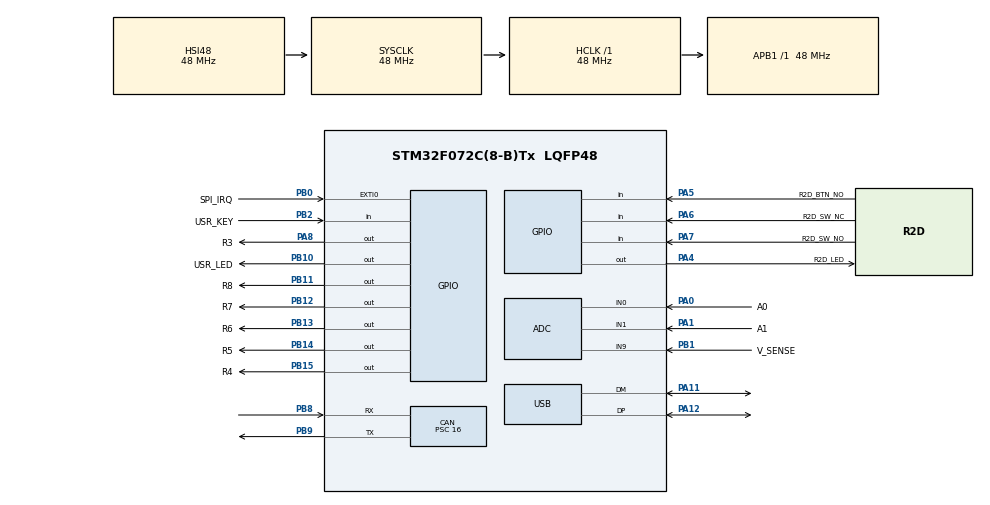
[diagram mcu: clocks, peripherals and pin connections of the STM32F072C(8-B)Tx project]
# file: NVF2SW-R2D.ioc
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ADC.ContinuousConvMode=DISABLE
CAN.BS1=CAN_BS1_3TQ
CAN.BS2=CAN_BS2_2TQ
CAN.CalculateBaudRate=500000
CAN.CalculateTimeBit=2000
CAN.CalculateTimeQuantum=333.3333333333333
CAN.Mode=CAN_MODE_NORMAL
CAN.Prescaler=16
CAN.TTCM=ENABLE
Mcu.Family=STM32F0
Mcu.Name=STM32F072C(8-B)Tx
Mcu.Package=LQFP48
NVIC.CEC_CAN_IRQn=true\:0\:0\:false\:false\:true\:true\:true\:true
NVIC.TIM16_IRQn=true\:0\:0\:false\:false\:true\:true\:true\:true
NVIC.USB_IRQn=true\:0\:0\:false\:false\:true\:false\:true\:true
PA0.GPIO_Label=A0
PA0.Mode=IN0
PA0.Signal=ADC_IN0
PA1.GPIO_Label=A1
PA1.Mode=IN1
PA1.Signal=ADC_IN1
PA11.Mode=Device
PA11.Signal=USB_DM
PA12.Mode=Device
PA12.Signal=USB_DP
PA13.Mode=Serial_Wire
PA13.Signal=SYS_SWDIO
PA14.Mode=Serial_Wire
PA14.Signal=SYS_SWCLK
PA4.GPIO_Label=R2D_LED
PA4.GPIO_ModeDefaultOutputPP=GPIO_MODE_OUTPUT_PP
PA4.GPIO_PuPd=GPIO_PULLUP
PA4.Signal=GPIO_Output
PA5.GPIO_Label=R2D_BTN_NO
PA5.GPIO_PuPd=GPIO_PULLDOWN
PA5.Signal=GPIO_Input
PA6.GPIO_Label=R2D_SW_NC
PA6.GPIO_PuPd=GPIO_PULLUP
PA6.Signal=GPIO_Input
PA7.GPIO_Label=R2D_SW_NO
PA7.GPIO_PuPd=GPIO_PULLDOWN
PA7.Signal=GPIO_Input
PA8.GPIO_Label=R3
PA8.Signal=GPIO_Output
PB0.GPIO_Label=SPI_IRQ
PB0.GPIO_ModeDefaultEXTI=GPIO_MODE_IT_RISING_FALLING
PB0.Signal=GPXTI0
PB1.GPIO_Label=V_SENSE
PB1.Mode=IN9
PB1.Signal=ADC_IN9
PB10.GPIO_Label=USR_LED
PB10.GPIO_ModeDefaultOutputPP=GPIO_MODE_OUTPUT_OD
PB10.GPIO_PuPd=GPIO_NOPULL
PB10.Signal=GPIO_Output
PB11.GPIO_Label=R8
PB11.Signal=GPIO_Output
PB12.GPIO_Label=R7
PB12.Signal=GPIO_Output
PB13.GPIO_Label=R6
PB13.Signal=GPIO_Output
PB14.GPIO_Label=R5
PB14.Signal=GPIO_Output
PB15.GPIO_Label=R4
PB15.Signal=GPIO_Output
PB2.GPIO_Label=USR_KEY
PB2.Signal=GPIO_Input
PB8.Mode=CAN_Activate
PB8.Signal=CAN_RX
PB9.Mode=CAN_Activate
PB9.Signal=CAN_TX
ProjectManager.HeapSize=0x200
ProjectManager.StackSize=0x400
ProjectManager.TargetToolchain=STM32CubeIDE
RCC.AHBFreq_Value=48000000
RCC.APB1Freq_Value=48000000
RCC.APB1TimFreq_Value=48000000
RCC.HCLKFreq_Value=48000000
RCC.SYSCLKFreq_VALUE=48000000
RCC.SYSCLKSource=RCC_SYSCLKSOURCE_HSI48
TIM16.AutoReloadPreload=TIM_AUTORELOAD_PRELOAD_ENABLE
TIM16.Period=10000-1
TIM16.Prescaler=480-1
USB_DEVICE.CLASS_NAME_FS=CDC
USB_DEVICE.MANUFACTURER_STRING=NVF2
USB_DEVICE.PRODUCT_STRING_CDC_FS=Small-General
USB_DEVICE.VirtualMode=Cdc
USB_DEVICE.VirtualModeFS=Cdc_FS
VP_ADC_TempSens_Input.Mode=IN-TempSens
VP_ADC_Vbat_Input.Mode=IN-Vbat
VP_ADC_Vref_Input.Mode=IN-Vrefint
VP_TIM15_VS_ClockSourceINT.Mode=Internal
VP_TIM16_VS_ClockSourceINT.Mode=Enable_Timer
VP_USB_DEVICE_VS_USB_DEVICE_CDC_FS.Mode=CDC_FS
board=custom

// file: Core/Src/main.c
/* USER CODE BEGIN Header */
/**
  ******************************************************************************
  * @file           : main.c
  * @brief          : Main program body
  ******************************************************************************
  * @attention
  *
  * Copyright (c) 2024 STMicroelectronics.
  * All rights reserved.
  *
  * This software is licensed under terms that can be found in the LICENSE file
  * in the root directory of this software component.
  * If no LICENSE file comes with this software, it is provided AS-IS.
  *
  ******************************************************************************
  */
/* USER CODE END Header */
#include "main.h"
#include "usb_device.h"

/* USER CODE BEGIN Includes */

#include "app.h"

/* USER CODE END Includes */

ADC_HandleTypeDef hadc;

CAN_HandleTypeDef hcan;

TIM_HandleTypeDef htim15;
TIM_HandleTypeDef htim16;

void SystemClock_Config(void);
static void MX_GPIO_Init(void);
static void MX_ADC_Init(void);
static void MX_CAN_Init(void);
static void MX_TIM16_Init(void);
static void MX_TIM15_Init(void);

/* USER CODE BEGIN 0 */
canbus_msg rxmsg;
void HAL_CAN_RxFifo0MsgPendingCallback(CAN_HandleTypeDef *hcan)
{
	static CAN_RxHeaderTypeDef rxHeader;
	cb_can_rx(hcan, &rxmsg, &rxHeader);
	cb_app(&rxmsg, &rxHeader);
}

void HAL_TIM_PeriodElapsedCallback(TIM_HandleTypeDef *htim)
{
  if (htim == &htim16)
  {
    task_app();
  }
}
/* USER CODE END 0 */

int main(void)
{

  /* MCU Configuration--------------------------------------------------------*/

  /* Reset of all peripherals, Initializes the Flash interface and the Systick. */
  HAL_Init();

  /* Configure the system clock */
  SystemClock_Config();

  /* Initialize all configured peripherals */
  MX_GPIO_Init();
  MX_ADC_Init();
  MX_CAN_Init();
  MX_USB_DEVICE_Init();
  MX_TIM16_Init();
  MX_TIM15_Init();
  /* USER CODE BEGIN 2 */
  HAL_TIM_Base_Start_IT(&htim16);

  init_app();
  /* USER CODE END 2 */

  /* Infinite loop */
  while (1)
  {

  }
}

void SystemClock_Config(void)
{
  RCC_OscInitTypeDef RCC_OscInitStruct = {0};
  RCC_ClkInitTypeDef RCC_ClkInitStruct = {0};
  RCC_PeriphCLKInitTypeDef PeriphClkInit = {0};

  /** Initializes the RCC Oscillators according to the specified parameters
  * in the RCC_OscInitTypeDef structure.
  */
  RCC_OscInitStruct.OscillatorType = RCC_OSCILLATORTYPE_HSI14|RCC_OSCILLATORTYPE_HSI48;
  RCC_OscInitStruct.HSI48State = RCC_HSI48_ON;
  RCC_OscInitStruct.HSI14State = RCC_HSI14_ON;
  RCC_OscInitStruct.HSI14CalibrationValue = 16;
  RCC_OscInitStruct.PLL.PLLState = RCC_PLL_NONE;
  if (HAL_RCC_OscConfig(&RCC_OscInitStruct) != HAL_OK)
  {
    Error_Handler();
  }

  /** Initializes the CPU, AHB and APB buses clocks
  */
  RCC_ClkInitStruct.ClockType = RCC_CLOCKTYPE_HCLK|RCC_CLOCKTYPE_SYSCLK
                              |RCC_CLOCKTYPE_PCLK1;
  RCC_ClkInitStruct.SYSCLKSource = RCC_SYSCLKSOURCE_HSI48;
  RCC_ClkInitStruct.AHBCLKDivider = RCC_SYSCLK_DIV1;
  RCC_ClkInitStruct.APB1CLKDivider = RCC_HCLK_DIV1;

  if (HAL_RCC_ClockConfig(&RCC_ClkInitStruct, FLASH_LATENCY_1) != HAL_OK)
  {
    Error_Handler();
  }
  PeriphClkInit.PeriphClockSelection = RCC_PERIPHCLK_USB;
  PeriphClkInit.UsbClockSelection = RCC_USBCLKSOURCE_HSI48;

  if (HAL_RCCEx_PeriphCLKConfig(&PeriphClkInit) != HAL_OK)
  {
    Error_Handler();
  }
}

static void MX_ADC_Init(void)
{

  ADC_ChannelConfTypeDef sConfig = {0};

  /** Configure the global features of the ADC (Clock, Resolution, Data Alignment and number of conversion)
  */
  hadc.Instance = ADC1;
  hadc.Init.ClockPrescaler = ADC_CLOCK_ASYNC_DIV1;
  hadc.Init.Resolution = ADC_RESOLUTION_12B;
  hadc.Init.DataAlign = ADC_DATAALIGN_RIGHT;
  hadc.Init.ScanConvMode = ADC_SCAN_DIRECTION_FORWARD;
  hadc.Init.EOCSelection = ADC_EOC_SINGLE_CONV;
  hadc.Init.LowPowerAutoWait = DISABLE;
  hadc.Init.LowPowerAutoPowerOff = DISABLE;
  hadc.Init.ContinuousConvMode = DISABLE;
  hadc.Init.DiscontinuousConvMode = DISABLE;
  hadc.Init.ExternalTrigConv = ADC_SOFTWARE_START;
  hadc.Init.ExternalTrigConvEdge = ADC_EXTERNALTRIGCONVEDGE_NONE;
  hadc.Init.DMAContinuousRequests = DISABLE;
  hadc.Init.Overrun = ADC_OVR_DATA_PRESERVED;
  if (HAL_ADC_Init(&hadc) != HAL_OK)
  {
    Error_Handler();
  }

  /** Configure for the selected ADC regular channel to be converted.
  */
  sConfig.Channel = ADC_CHANNEL_0;
  sConfig.Rank = ADC_RANK_CHANNEL_NUMBER;
  sConfig.SamplingTime = ADC_SAMPLETIME_1CYCLE_5;
  if (HAL_ADC_ConfigChannel(&hadc, &sConfig) != HAL_OK)
  {
    Error_Handler();
  }

  /** Configure for the selected ADC regular channel to be converted.
  */
  sConfig.Channel = ADC_CHANNEL_1;
  if (HAL_ADC_ConfigChannel(&hadc, &sConfig) != HAL_OK)
  {
    Error_Handler();
  }

  /** Configure for the selected ADC regular channel to be converted.
  */
  sConfig.Channel = ADC_CHANNEL_9;
  if (HAL_ADC_ConfigChannel(&hadc, &sConfig) != HAL_OK)
  {
    Error_Handler();
  }

  /** Configure for the selected ADC regular channel to be converted.
  */
  sConfig.Channel = ADC_CHANNEL_TEMPSENSOR;
  if (HAL_ADC_ConfigChannel(&hadc, &sConfig) != HAL_OK)
  {
    Error_Handler();
  }

  /** Configure for the selected ADC regular channel to be converted.
  */
  sConfig.Channel = ADC_CHANNEL_VREFINT;
  if (HAL_ADC_ConfigChannel(&hadc, &sConfig) != HAL_OK)
  {
    Error_Handler();
  }

  /** Configure for the selected ADC regular channel to be converted.
  */
  sConfig.Channel = ADC_CHANNEL_VBAT;
  if (HAL_ADC_ConfigChannel(&hadc, &sConfig) != HAL_OK)
  {
    Error_Handler();
  }

}

static void MX_CAN_Init(void)
{

  hcan.Instance = CAN;
  hcan.Init.Prescaler = 16;
  hcan.Init.Mode = CAN_MODE_NORMAL;
  hcan.Init.SyncJumpWidth = CAN_SJW_1TQ;
  hcan.Init.TimeSeg1 = CAN_BS1_3TQ;
  hcan.Init.TimeSeg2 = CAN_BS2_2TQ;
  hcan.Init.TimeTriggeredMode = ENABLE;
  hcan.Init.AutoBusOff = DISABLE;
  hcan.Init.AutoWakeUp = DISABLE;
  hcan.Init.AutoRetransmission = DISABLE;
  hcan.Init.ReceiveFifoLocked = DISABLE;
  hcan.Init.TransmitFifoPriority = DISABLE;
  if (HAL_CAN_Init(&hcan) != HAL_OK)
  {
    Error_Handler();
  }

}

static void MX_TIM15_Init(void)
{

  TIM_ClockConfigTypeDef sClockSourceConfig = {0};
  TIM_MasterConfigTypeDef sMasterConfig = {0};

  htim15.Instance = TIM15;
  htim15.Init.Prescaler = 0;
  htim15.Init.CounterMode = TIM_COUNTERMODE_UP;
  htim15.Init.Period = 65535;
  htim15.Init.ClockDivision = TIM_CLOCKDIVISION_DIV1;
  htim15.Init.RepetitionCounter = 0;
  htim15.Init.AutoReloadPreload = TIM_AUTORELOAD_PRELOAD_DISABLE;
  if (HAL_TIM_Base_Init(&htim15) != HAL_OK)
  {
    Error_Handler();
  }
  sClockSourceConfig.ClockSource = TIM_CLOCKSOURCE_INTERNAL;
  if (HAL_TIM_ConfigClockSource(&htim15, &sClockSourceConfig) != HAL_OK)
  {
    Error_Handler();
  }
  sMasterConfig.MasterOutputTrigger = TIM_TRGO_RESET;
  sMasterConfig.MasterSlaveMode = TIM_MASTERSLAVEMODE_DISABLE;
  if (HAL_TIMEx_MasterConfigSynchronization(&htim15, &sMasterConfig) != HAL_OK)
  {
    Error_Handler();
  }

}

static void MX_TIM16_Init(void)
{

  htim16.Instance = TIM16;
  htim16.Init.Prescaler = 480-1;
  htim16.Init.CounterMode = TIM_COUNTERMODE_UP;
  htim16.Init.Period = 10000-1;
  htim16.Init.ClockDivision = TIM_CLOCKDIVISION_DIV1;
  htim16.Init.RepetitionCounter = 0;
  htim16.Init.AutoReloadPreload = TIM_AUTORELOAD_PRELOAD_ENABLE;
  if (HAL_TIM_Base_Init(&htim16) != HAL_OK)
  {
    Error_Handler();
  }

}

static void MX_GPIO_Init(void)
{
  GPIO_InitTypeDef GPIO_InitStruct = {0};

  /* GPIO Ports Clock Enable */
  __HAL_RCC_GPIOC_CLK_ENABLE();
  __HAL_RCC_GPIOF_CLK_ENABLE();
  __HAL_RCC_GPIOA_CLK_ENABLE();
  __HAL_RCC_GPIOB_CLK_ENABLE();

  /*Configure GPIO pin Output Level */
  HAL_GPIO_WritePin(GPIOA, R2D_LED_Pin|R3_Pin, GPIO_PIN_RESET);

  /*Configure GPIO pin Output Level */
  HAL_GPIO_WritePin(GPIOB, USR_LED_Pin|R8_Pin|R7_Pin|R6_Pin
                          |R5_Pin|R4_Pin, GPIO_PIN_RESET);

  /*Configure GPIO pins : PC13 PC14 PC15 */
  GPIO_InitStruct.Pin = GPIO_PIN_13|GPIO_PIN_14|GPIO_PIN_15;
  GPIO_InitStruct.Mode = GPIO_MODE_ANALOG;
  GPIO_InitStruct.Pull = GPIO_NOPULL;
  HAL_GPIO_Init(GPIOC, &GPIO_InitStruct);

  /*Configure GPIO pins : PF0 PF1 */
  GPIO_InitStruct.Pin = GPIO_PIN_0|GPIO_PIN_1;
  GPIO_InitStruct.Mode = GPIO_MODE_ANALOG;
  GPIO_InitStruct.Pull = GPIO_NOPULL;
  HAL_GPIO_Init(GPIOF, &GPIO_InitStruct);

  /*Configure GPIO pins : PA2 PA3 PA9 PA10
                           PA15 */
  GPIO_InitStruct.Pin = GPIO_PIN_2|GPIO_PIN_3|GPIO_PIN_9|GPIO_PIN_10
                          |GPIO_PIN_15;
  GPIO_InitStruct.Mode = GPIO_MODE_ANALOG;
  GPIO_InitStruct.Pull = GPIO_NOPULL;
  HAL_GPIO_Init(GPIOA, &GPIO_InitStruct);

  /*Configure GPIO pin : R2D_LED_Pin */
  GPIO_InitStruct.Pin = R2D_LED_Pin;
  GPIO_InitStruct.Mode = GPIO_MODE_OUTPUT_PP;
  GPIO_InitStruct.Pull = GPIO_PULLUP;
  GPIO_InitStruct.Speed = GPIO_SPEED_FREQ_LOW;
  HAL_GPIO_Init(R2D_LED_GPIO_Port, &GPIO_InitStruct);

  /*Configure GPIO pins : R2D_BTN_NO_Pin R2D_SW_NO_Pin */
  GPIO_InitStruct.Pin = R2D_BTN_NO_Pin|R2D_SW_NO_Pin;
  GPIO_InitStruct.Mode = GPIO_MODE_INPUT;
  GPIO_InitStruct.Pull = GPIO_PULLDOWN;
  HAL_GPIO_Init(GPIOA, &GPIO_InitStruct);

  /*Configure GPIO pin : R2D_SW_NC_Pin */
  GPIO_InitStruct.Pin = R2D_SW_NC_Pin;
  GPIO_InitStruct.Mode = GPIO_MODE_INPUT;
  GPIO_InitStruct.Pull = GPIO_PULLUP;
  HAL_GPIO_Init(R2D_SW_NC_GPIO_Port, &GPIO_InitStruct);

  /*Configure GPIO pin : SPI_IRQ_Pin */
  GPIO_InitStruct.Pin = SPI_IRQ_Pin;
  GPIO_InitStruct.Mode = GPIO_MODE_IT_RISING_FALLING;
  GPIO_InitStruct.Pull = GPIO_NOPULL;
  HAL_GPIO_Init(SPI_IRQ_GPIO_Port, &GPIO_InitStruct);

  /*Configure GPIO pin : USR_KEY_Pin */
  GPIO_InitStruct.Pin = USR_KEY_Pin;
  GPIO_InitStruct.Mode = GPIO_MODE_INPUT;
  GPIO_InitStruct.Pull = GPIO_NOPULL;
  HAL_GPIO_Init(USR_KEY_GPIO_Port, &GPIO_InitStruct);

  /*Configure GPIO pin : USR_LED_Pin */
  GPIO_InitStruct.Pin = USR_LED_Pin;
  GPIO_InitStruct.Mode = GPIO_MODE_OUTPUT_OD;
  GPIO_InitStruct.Pull = GPIO_NOPULL;
  GPIO_InitStruct.Speed = GPIO_SPEED_FREQ_LOW;
  HAL_GPIO_Init(USR_LED_GPIO_Port, &GPIO_InitStruct);

  /*Configure GPIO pins : R8_Pin R7_Pin R6_Pin R5_Pin
                           R4_Pin */
  GPIO_InitStruct.Pin = R8_Pin|R7_Pin|R6_Pin|R5_Pin
                          |R4_Pin;
  GPIO_InitStruct.Mode = GPIO_MODE_OUTPUT_PP;
  GPIO_InitStruct.Pull = GPIO_NOPULL;
  GPIO_InitStruct.Speed = GPIO_SPEED_FREQ_LOW;
  HAL_GPIO_Init(GPIOB, &GPIO_InitStruct);

  /*Configure GPIO pin : R3_Pin */
  GPIO_InitStruct.Pin = R3_Pin;
  GPIO_InitStruct.Mode = GPIO_MODE_OUTPUT_PP;
  GPIO_InitStruct.Pull = GPIO_NOPULL;
  GPIO_InitStruct.Speed = GPIO_SPEED_FREQ_LOW;
  HAL_GPIO_Init(R3_GPIO_Port, &GPIO_InitStruct);

  /*Configure GPIO pins : PB3 PB4 PB5 PB6
                           PB7 */
  GPIO_InitStruct.Pin = GPIO_PIN_3|GPIO_PIN_4|GPIO_PIN_5|GPIO_PIN_6
                          |GPIO_PIN_7;
  GPIO_InitStruct.Mode = GPIO_MODE_ANALOG;
  GPIO_InitStruct.Pull = GPIO_NOPULL;
  HAL_GPIO_Init(GPIOB, &GPIO_InitStruct);

}

void Error_Handler(void)
{
  __disable_irq();
  while (1)
  {
  }
}
